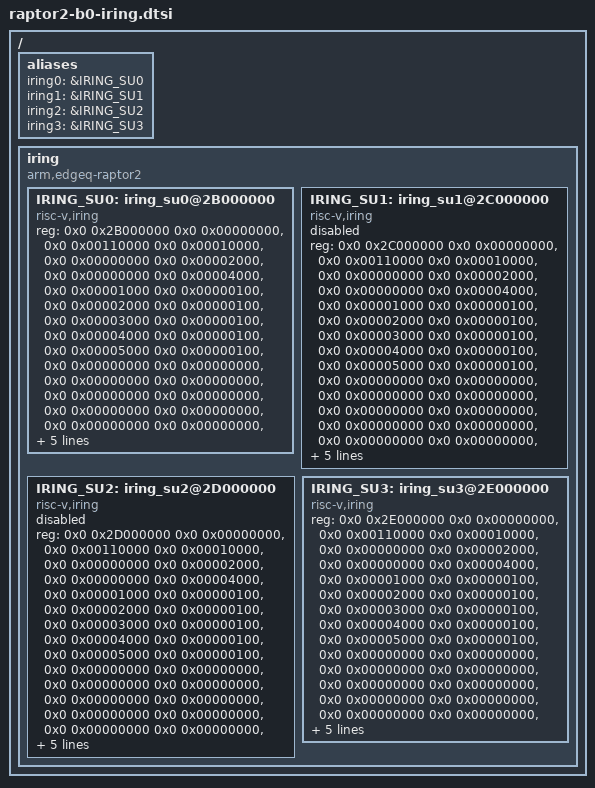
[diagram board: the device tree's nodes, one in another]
// SPDX-License-Identifier: GPL-2.0
/*
 * EdgeQ Inc.
 *
 * EdgeQ Raptor2 IRING DTS
 */

/ {
	aliases {
		iring0 = &IRING_SU0;
		iring1 = &IRING_SU1;
		iring2 = &IRING_SU2;
		iring3 = &IRING_SU3;
	};

	iring {
		compatible = "arm,edgeq-raptor2";
		#address-cells = <2>;
		#size-cells = <2>;

		IRING_SU0: iring_su0@2B000000 {
			compatible = "risc-v,iring";
			device_type = "su";
			#address-cells = <2>;
			#size-cells = <2>;
			ranges;
			reg =	<0x0 0x2B000000 0x0 0x00000000>,
				<0x0 0x00110000 0x0 0x00010000>,
				<0x0 0x00000000 0x0 0x00002000>,
				<0x0 0x00000000 0x0 0x00004000>,
				<0x0 0x00001000 0x0 0x00000100>,
				<0x0 0x00002000 0x0 0x00000100>,
				<0x0 0x00003000 0x0 0x00000100>,
				<0x0 0x00004000 0x0 0x00000100>,
				<0x0 0x00005000 0x0 0x00000100>,
				<0x0 0x00000000 0x0 0x00000000>,
				<0x0 0x00000000 0x0 0x00000000>,
				<0x0 0x00000000 0x0 0x00000000>,
				<0x0 0x00000000 0x0 0x00000000>,
				<0x0 0x00000000 0x0 0x00000000>,
				<0x0 0x00000000 0x0 0x00010000>,
				<0x0 0x00080000 0x0 0x00020000>;
			reg-names = "sudev_base", "cpu", "d-cache", "i-cache", "suinfo_offset",
				"suconf_offset", "suau_offset", "sustats_offset", "sudbg_offset",
				"lmem_addr_local_wb", "lmem_addr_local_unc", "lmem_addr_local_wt",
				"lmem_e1", "lmem_e1_b2", "ilmoffs", "dlmoffs";
			enable-method = "reset-vector";
			sudev = <&SUDEV>;
			sumem = <&SUMEM>;
			status = "okay";
		};

		IRING_SU1: iring_su1@2C000000 {
			compatible = "risc-v,iring";
			device_type = "su";
			#address-cells = <2>;
			#size-cells = <2>;
			ranges;
			reg =	<0x0 0x2C000000 0x0 0x00000000>,
				<0x0 0x00110000 0x0 0x00010000>,
				<0x0 0x00000000 0x0 0x00002000>,
				<0x0 0x00000000 0x0 0x00004000>,
				<0x0 0x00001000 0x0 0x00000100>,
				<0x0 0x00002000 0x0 0x00000100>,
				<0x0 0x00003000 0x0 0x00000100>,
				<0x0 0x00004000 0x0 0x00000100>,
				<0x0 0x00005000 0x0 0x00000100>,
				<0x0 0x00000000 0x0 0x00000000>,
				<0x0 0x00000000 0x0 0x00000000>,
				<0x0 0x00000000 0x0 0x00000000>,
				<0x0 0x00000000 0x0 0x00000000>,
				<0x0 0x00000000 0x0 0x00000000>,
				<0x0 0x00000000 0x0 0x00010000>,
				<0x0 0x00080000 0x0 0x00020000>;
			reg-names = "sudev_base", "cpu", "d-cache", "i-cache", "suinfo_offset",
				"suconf_offset", "suau_offset", "sustats_offset", "sudbg_offset",
				"lmem_addr_local_wb", "lmem_addr_local_unc", "lmem_addr_local_wt",
				"lmem_e1", "lmem_e1_b2", "ilmoffs", "dlmoffs";
			enable-method = "reset-vector";
			sudev = <&SUDEV>;
			sumem = <&SUMEM>;
			status = "disabled";
		};

		IRING_SU2: iring_su2@2D000000 {
			compatible = "risc-v,iring";
			device_type = "su";
			#address-cells = <2>;
			#size-cells = <2>;
			ranges;
			reg =	<0x0 0x2D000000 0x0 0x00000000>,
				<0x0 0x00110000 0x0 0x00010000>,
				<0x0 0x00000000 0x0 0x00002000>,
				<0x0 0x00000000 0x0 0x00004000>,
				<0x0 0x00001000 0x0 0x00000100>,
				<0x0 0x00002000 0x0 0x00000100>,
				<0x0 0x00003000 0x0 0x00000100>,
				<0x0 0x00004000 0x0 0x00000100>,
				<0x0 0x00005000 0x0 0x00000100>,
				<0x0 0x00000000 0x0 0x00000000>,
				<0x0 0x00000000 0x0 0x00000000>,
				<0x0 0x00000000 0x0 0x00000000>,
				<0x0 0x00000000 0x0 0x00000000>,
				<0x0 0x00000000 0x0 0x00000000>,
				<0x0 0x00000000 0x0 0x00010000>,
				<0x0 0x00080000 0x0 0x00020000>;
			reg-names = "sudev_base", "cpu", "d-cache", "i-cache", "suinfo_offset",
				"suconf_offset", "suau_offset", "sustats_offset", "sudbg_offset",
				"lmem_addr_local_wb", "lmem_addr_local_unc", "lmem_addr_local_wt",
				"lmem_e1", "lmem_e1_b2", "ilmoffs", "dlmoffs";
			enable-method = "reset-vector";
			sudev = <&SUDEV>;
			sumem = <&SUMEM>;
			status = "disabled";
		};

		IRING_SU3: iring_su3@2E000000 {
			compatible = "risc-v,iring";
			device_type = "su";
			#address-cells = <2>;
			#size-cells = <2>;
			ranges;
			reg =	<0x0 0x2E000000 0x0 0x00000000>,
				<0x0 0x00110000 0x0 0x00010000>,
				<0x0 0x00000000 0x0 0x00002000>,
				<0x0 0x00000000 0x0 0x00004000>,
				<0x0 0x00001000 0x0 0x00000100>,
				<0x0 0x00002000 0x0 0x00000100>,
				<0x0 0x00003000 0x0 0x00000100>,
				<0x0 0x00004000 0x0 0x00000100>,
				<0x0 0x00005000 0x0 0x00000100>,
				<0x0 0x00000000 0x0 0x00000000>,
				<0x0 0x00000000 0x0 0x00000000>,
				<0x0 0x00000000 0x0 0x00000000>,
				<0x0 0x00000000 0x0 0x00000000>,
				<0x0 0x00000000 0x0 0x00000000>,
				<0x0 0x00000000 0x0 0x00010000>,
				<0x0 0x00080000 0x0 0x00020000>;
			reg-names = "sudev_base", "cpu", "d-cache", "i-cache", "suinfo_offset",
				"suconf_offset", "suau_offset", "sustats_offset", "sudbg_offset",
				"lmem_addr_local_wb", "lmem_addr_local_unc", "lmem_addr_local_wt",
				"lmem_e1", "lmem_e1_b2", "ilmoffs", "dlmoffs";
			enable-method = "reset-vector";
			sudev = <&SUDEV>;
			sumem = <&SUMEM>;
			status = "okay";
		};

	};
};
